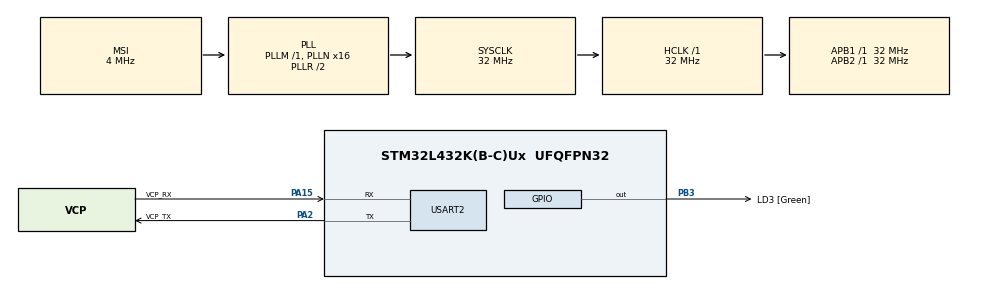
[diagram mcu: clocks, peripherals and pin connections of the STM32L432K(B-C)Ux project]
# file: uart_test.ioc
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Dma.Request0=USART2_TX
Dma.USART2_TX.0.Direction=DMA_MEMORY_TO_PERIPH
Dma.USART2_TX.0.Instance=DMA1_Channel7
Dma.USART2_TX.0.MemDataAlignment=DMA_MDATAALIGN_BYTE
Dma.USART2_TX.0.MemInc=DMA_MINC_ENABLE
Dma.USART2_TX.0.Mode=DMA_NORMAL
Dma.USART2_TX.0.PeriphDataAlignment=DMA_PDATAALIGN_BYTE
Dma.USART2_TX.0.PeriphInc=DMA_PINC_DISABLE
Dma.USART2_TX.0.Priority=DMA_PRIORITY_LOW
Mcu.Family=STM32L4
Mcu.Name=STM32L432K(B-C)Ux
Mcu.Package=UFQFPN32
NVIC.DMA1_Channel7_IRQn=true\:0\:0\:false\:false\:true\:false\:true\:true
NVIC.PriorityGroup=NVIC_PRIORITYGROUP_4
NVIC.TIM7_IRQn=true\:7\:0\:true\:false\:true\:true\:true\:true
NVIC.USART2_IRQn=true\:0\:0\:false\:false\:true\:true\:true\:true
PA0.GPIO_Label=MCO [High speed clock in]
PA0.Mode=HSE-External-Clock-Source-for-LittleOrca
PA0.Signal=RCC_CK_IN
PA13\ (JTMS-SWDIO).GPIO_Label=SWDIO
PA13\ (JTMS-SWDIO).Mode=Serial_Wire
PA13\ (JTMS-SWDIO).Signal=SYS_JTMS-SWDIO
PA14\ (JTCK-SWCLK).GPIO_Label=SWCLK
PA14\ (JTCK-SWCLK).Mode=Serial_Wire
PA14\ (JTCK-SWCLK).Signal=SYS_JTCK-SWCLK
PA15\ (JTDI).GPIO_Label=VCP_RX
PA15\ (JTDI).Mode=Asynchronous
PA15\ (JTDI).Signal=USART2_RX
PA2.GPIO_Label=VCP_TX
PA2.Mode=Asynchronous
PA2.Signal=USART2_TX
PB3\ (JTDO-TRACESWO).GPIO_Label=LD3 [Green]
PB3\ (JTDO-TRACESWO).Signal=GPIO_Output
PC14-OSC32_IN\ (PC14).Mode=LSE-External-Oscillator
PC14-OSC32_IN\ (PC14).Signal=RCC_OSC32_IN
PC15-OSC32_OUT\ (PC15).Mode=LSE-External-Oscillator
PC15-OSC32_OUT\ (PC15).Signal=RCC_OSC32_OUT
ProjectManager.HeapSize=0x200
ProjectManager.StackSize=0x400
ProjectManager.TargetToolchain=CMake
RCC.AHBFreq_Value=32000000
RCC.APB1Freq_Value=32000000
RCC.APB1TimFreq_Value=32000000
RCC.APB2Freq_Value=32000000
RCC.APB2TimFreq_Value=32000000
RCC.CortexFreq_Value=32000000
RCC.HCLKFreq_Value=32000000
RCC.HSE_VALUE=8000000
RCC.HSI16_VALUE=16000000
RCC.HSI48_VALUE=48000000
RCC.HSI_VALUE=16000000
RCC.MSI_VALUE=4000000
RCC.PLLMUL=RCC_PLLMUL_4
RCC.PLLN=16
RCC.SYSCLKFreq_VALUE=32000000
RCC.SYSCLKSource=RCC_SYSCLKSOURCE_PLLCLK
RCC.VCOOutputFreq_Value=64000000
TIM7.Period=100-1
TIM7.Prescaler=32000-1
USART2.VirtualMode-Asynchronous=VM_ASYNC
VP_TIM7_VS_ClockSourceINT.Mode=Enable_Timer
board=NUCLEO-L432KC

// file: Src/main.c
/* USER CODE BEGIN Header */
/**
  ******************************************************************************
  * @file           : main.c
  * @brief          : Main program body
  ******************************************************************************
  * @attention
  *
  * Copyright (c) 2025 STMicroelectronics.
  * All rights reserved.
  *
  * This software is licensed under terms that can be found in the LICENSE file
  * in the root directory of this software component.
  * If no LICENSE file comes with this software, it is provided AS-IS.
  *
  ******************************************************************************
  */
/* USER CODE END Header */
#include "main.h"

/* USER CODE BEGIN Includes */
#include <stdio.h>

/* USER CODE END Includes */

TIM_HandleTypeDef htim7;

UART_HandleTypeDef huart2;
DMA_HandleTypeDef hdma_usart2_tx;

/* USER CODE BEGIN PV */

TIM_HandleTypeDef htim7;

UART_HandleTypeDef huart2;

volatile uint32_t counter;

/* USER CODE END PV */

void SystemClock_Config(void);
static void MX_GPIO_Init(void);
static void MX_DMA_Init(void);
static void MX_USART2_UART_Init(void);
static void MX_TIM7_Init(void);

/* USER CODE BEGIN 0 */
int __io_putchar(int ch) {
    while (!(USART2->ISR & USART_ISR_TXE)) {}
    USART2->TDR = (ch & 0xFF);
    return ch;
}

void HAL_TIM_PeriodElapsedCallback(TIM_HandleTypeDef *htim) {
  static uint32_t last_counter;
  HAL_GPIO_TogglePin(LD3_GPIO_Port, LD3_Pin);
  printf("counter: %ld\n", counter - last_counter);
  last_counter = counter;
  //HAL_UART_Transmit(&huart2, (uint8_t*)"Moege dein WLAN immer stark sein. Frohes neues Jahr!\n", 54, HAL_MAX_DELAY); //via Polling
  //HAL_UART_Transmit_IT(&huart2, (uint8_t*)"Moege dein WLAN immer stark sein. Frohes neues Jahr!\n", 54); //via Interrupt
  //HAL_UART_Transmit_DMA(&huart2, (uint8_t*)"Moege dein WLAN immer stark sein. Frohes neues Jahr!\n", 54); //via DMA
}

/* USER CODE END 0 */

int main(void)
{

  /* MCU Configuration--------------------------------------------------------*/

  /* Reset of all peripherals, Initializes the Flash interface and the Systick. */
  HAL_Init();

  /* Configure the system clock */
  SystemClock_Config();

  /* Initialize all configured peripherals */
  MX_GPIO_Init();
  MX_DMA_Init();
  MX_USART2_UART_Init();
  MX_TIM7_Init();
  /* USER CODE BEGIN 2 */
  HAL_TIM_Base_Start_IT(&htim7);
  printf("hello, world\n");
  /* USER CODE END 2 */

  /* Infinite loop */
  /* USER CODE BEGIN WHILE */
  while (1)
  {
    counter++;
    /* USER CODE END WHILE */

  }
}

void SystemClock_Config(void)
{
  RCC_OscInitTypeDef RCC_OscInitStruct = {0};
  RCC_ClkInitTypeDef RCC_ClkInitStruct = {0};

  /** Configure the main internal regulator output voltage
  */
  if (HAL_PWREx_ControlVoltageScaling(PWR_REGULATOR_VOLTAGE_SCALE1) != HAL_OK)
  {
    Error_Handler();
  }

  /** Configure LSE Drive Capability
  */
  HAL_PWR_EnableBkUpAccess();
  __HAL_RCC_LSEDRIVE_CONFIG(RCC_LSEDRIVE_LOW);

  /** Initializes the RCC Oscillators according to the specified parameters
  * in the RCC_OscInitTypeDef structure.
  */
  RCC_OscInitStruct.OscillatorType = RCC_OSCILLATORTYPE_LSE|RCC_OSCILLATORTYPE_MSI;
  RCC_OscInitStruct.LSEState = RCC_LSE_ON;
  RCC_OscInitStruct.MSIState = RCC_MSI_ON;
  RCC_OscInitStruct.MSICalibrationValue = 0;
  RCC_OscInitStruct.MSIClockRange = RCC_MSIRANGE_6;
  RCC_OscInitStruct.PLL.PLLState = RCC_PLL_ON;
  RCC_OscInitStruct.PLL.PLLSource = RCC_PLLSOURCE_MSI;
  RCC_OscInitStruct.PLL.PLLM = 1;
  RCC_OscInitStruct.PLL.PLLN = 16;
  RCC_OscInitStruct.PLL.PLLP = RCC_PLLP_DIV7;
  RCC_OscInitStruct.PLL.PLLQ = RCC_PLLQ_DIV2;
  RCC_OscInitStruct.PLL.PLLR = RCC_PLLR_DIV2;
  if (HAL_RCC_OscConfig(&RCC_OscInitStruct) != HAL_OK)
  {
    Error_Handler();
  }

  /** Initializes the CPU, AHB and APB buses clocks
  */
  RCC_ClkInitStruct.ClockType = RCC_CLOCKTYPE_HCLK|RCC_CLOCKTYPE_SYSCLK
                              |RCC_CLOCKTYPE_PCLK1|RCC_CLOCKTYPE_PCLK2;
  RCC_ClkInitStruct.SYSCLKSource = RCC_SYSCLKSOURCE_PLLCLK;
  RCC_ClkInitStruct.AHBCLKDivider = RCC_SYSCLK_DIV1;
  RCC_ClkInitStruct.APB1CLKDivider = RCC_HCLK_DIV1;
  RCC_ClkInitStruct.APB2CLKDivider = RCC_HCLK_DIV1;

  if (HAL_RCC_ClockConfig(&RCC_ClkInitStruct, FLASH_LATENCY_1) != HAL_OK)
  {
    Error_Handler();
  }

  /** Enable MSI Auto calibration
  */
  HAL_RCCEx_EnableMSIPLLMode();
}

static void MX_TIM7_Init(void)
{

  TIM_MasterConfigTypeDef sMasterConfig = {0};

  htim7.Instance = TIM7;
  htim7.Init.Prescaler = 32000-1;
  htim7.Init.CounterMode = TIM_COUNTERMODE_UP;
  htim7.Init.Period = 100-1;
  htim7.Init.AutoReloadPreload = TIM_AUTORELOAD_PRELOAD_DISABLE;
  if (HAL_TIM_Base_Init(&htim7) != HAL_OK)
  {
    Error_Handler();
  }
  sMasterConfig.MasterOutputTrigger = TIM_TRGO_RESET;
  sMasterConfig.MasterSlaveMode = TIM_MASTERSLAVEMODE_DISABLE;
  if (HAL_TIMEx_MasterConfigSynchronization(&htim7, &sMasterConfig) != HAL_OK)
  {
    Error_Handler();
  }

}

static void MX_USART2_UART_Init(void)
{

  huart2.Instance = USART2;
  huart2.Init.BaudRate = 115200;
  huart2.Init.WordLength = UART_WORDLENGTH_8B;
  huart2.Init.StopBits = UART_STOPBITS_1;
  huart2.Init.Parity = UART_PARITY_NONE;
  huart2.Init.Mode = UART_MODE_TX_RX;
  huart2.Init.HwFlowCtl = UART_HWCONTROL_NONE;
  huart2.Init.OverSampling = UART_OVERSAMPLING_16;
  huart2.Init.OneBitSampling = UART_ONE_BIT_SAMPLE_DISABLE;
  huart2.AdvancedInit.AdvFeatureInit = UART_ADVFEATURE_NO_INIT;
  if (HAL_UART_Init(&huart2) != HAL_OK)
  {
    Error_Handler();
  }

}

static void MX_DMA_Init(void)
{

  /* DMA controller clock enable */
  __HAL_RCC_DMA1_CLK_ENABLE();

  /* DMA interrupt init */
  /* DMA1_Channel7_IRQn interrupt configuration */
  HAL_NVIC_SetPriority(DMA1_Channel7_IRQn, 0, 0);
  HAL_NVIC_EnableIRQ(DMA1_Channel7_IRQn);

}

static void MX_GPIO_Init(void)
{
  GPIO_InitTypeDef GPIO_InitStruct = {0};

  /* GPIO Ports Clock Enable */
  __HAL_RCC_GPIOC_CLK_ENABLE();
  __HAL_RCC_GPIOA_CLK_ENABLE();
  __HAL_RCC_GPIOB_CLK_ENABLE();

  /*Configure GPIO pin Output Level */
  HAL_GPIO_WritePin(LD3_GPIO_Port, LD3_Pin, GPIO_PIN_RESET);

  /*Configure GPIO pin : LD3_Pin */
  GPIO_InitStruct.Pin = LD3_Pin;
  GPIO_InitStruct.Mode = GPIO_MODE_OUTPUT_PP;
  GPIO_InitStruct.Pull = GPIO_NOPULL;
  GPIO_InitStruct.Speed = GPIO_SPEED_FREQ_LOW;
  HAL_GPIO_Init(LD3_GPIO_Port, &GPIO_InitStruct);

}

void Error_Handler(void)
{
  __disable_irq();
  while (1)
  {
  }
}
